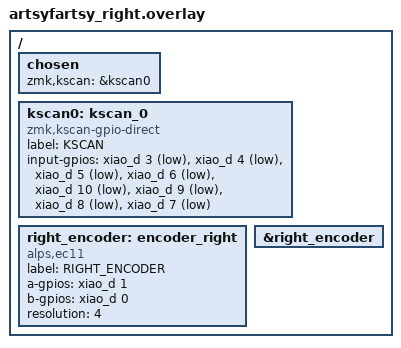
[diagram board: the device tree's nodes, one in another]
/*
 * Copyright (c) 2021 Mike "KemoNine" Crosson
 *
 * SPDX-License-Identifier: MIT
 */

#include <dt-bindings/zmk/matrix_transform.h>

/ {
	chosen {
		zmk,kscan = &kscan0;
	};
	
	kscan0: kscan_0 {
		compatible = "zmk,kscan-gpio-direct";

		label = "KSCAN";

		input-gpios
			= <&xiao_d 3 (GPIO_ACTIVE_LOW | GPIO_PULL_UP)>
            , <&xiao_d 4 (GPIO_ACTIVE_LOW | GPIO_PULL_UP)>
            , <&xiao_d 5 (GPIO_ACTIVE_LOW | GPIO_PULL_UP)>
            , <&xiao_d 6 (GPIO_ACTIVE_LOW | GPIO_PULL_UP)>
            , <&xiao_d 10 (GPIO_ACTIVE_LOW | GPIO_PULL_UP)>
            , <&xiao_d 9 (GPIO_ACTIVE_LOW | GPIO_PULL_UP)>
            , <&xiao_d 8 (GPIO_ACTIVE_LOW | GPIO_PULL_UP)>
            , <&xiao_d 7 (GPIO_ACTIVE_LOW | GPIO_PULL_UP)>
            ;
	};
	
	right_encoder: encoder_right {
        compatible = "alps,ec11";
        label = "RIGHT_ENCODER";
        a-gpios = <&xiao_d 1 (GPIO_ACTIVE_HIGH | GPIO_PULL_UP)>;
        b-gpios = <&xiao_d 0 (GPIO_ACTIVE_HIGH | GPIO_PULL_UP)>;
        resolution = <4>;
    };
	
	&right_encoder {
		status = "okay";
	};
};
